# STC32G144K246 register map
Vendor: STC; File version: 2.0
Registers are 8-bit, read-write, no defined reset value unless marked. A register's access mark holds for its fields unless they carry their own. Offsets are from the block's base; [hi:lo] are bit positions; {n}, {i} and the like mark numbered series.

## GPIO7 — P7 端口、模式、上下拉和中断
Base 0x007EFD07
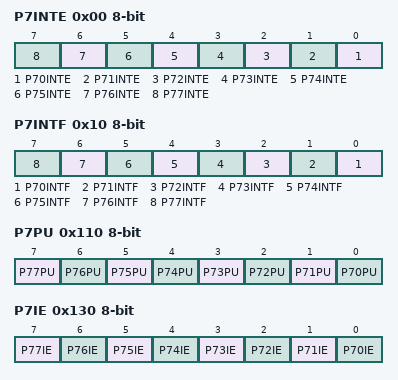
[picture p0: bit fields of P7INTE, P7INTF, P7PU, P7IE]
0x00 P7INTE — P7口中断使能寄存器
  [n-70] P{n}INTE (n=70..77) — 尚未自动匹配到此字段的独立说明；请查看下方章节说明。
0x10 P7INTF ro — P7口中断标志寄存器
  [n-70] P{n}INTF (n=70..77) — 尚未自动匹配到此字段的独立说明；请查看下方章节说明。
0x110 P7PU — P7口上拉电阻控制寄存器
  [all] fields
    0=禁止内部上拉电阻; 1=使能内部上拉电阻
  [7] P77PU — 控制 P7.7 的内部上拉电阻。
  [6] P76PU — 控制 P7.6 的内部上拉电阻。
  [5] P75PU — 控制 P7.5 的内部上拉电阻。
  [4] P74PU — 控制 P7.4 的内部上拉电阻。
  [3] P73PU — 控制 P7.3 的内部上拉电阻。
  [2] P72PU — 控制 P7.2 的内部上拉电阻。
  [1] P71PU — 控制 P7.1 的内部上拉电阻。
  [0] P70PU — 控制 P7.0 的内部上拉电阻。
0x130 P7IE — P7口输入使能控制寄存器
  [all] fields
    0=禁止数字信号输入，用于模拟功能; 1=使能数字信号输入
  [7] P77IE — 控制 P7.7 的数字信号输入。
  [6] P76IE — 控制 P7.6 的数字信号输入。
  [5] P75IE — 控制 P7.5 的数字信号输入。
  [4] P74IE — 控制 P7.4 的数字信号输入。
  [3] P73IE — 控制 P7.3 的数字信号输入。
  [2] P72IE — 控制 P7.2 的数字信号输入。
  [1] P71IE — 控制 P7.1 的数字信号输入。
  [0] P70IE — 控制 P7.0 的数字信号输入。
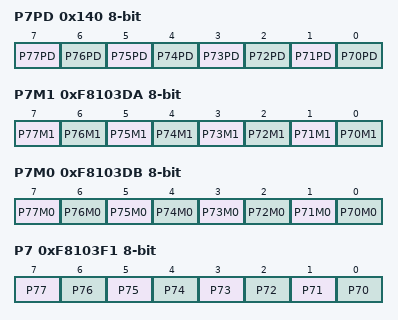
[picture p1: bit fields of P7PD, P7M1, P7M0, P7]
0x140 P7PD — P7口下拉电阻控制寄存器
  [all] fields
    0=禁止内部下拉电阻; 1=使能内部下拉电阻
  [7] P77PD — 控制 P7.7 的内部下拉电阻。
  [6] P76PD — 控制 P7.6 的内部下拉电阻。
  [5] P75PD — 控制 P7.5 的内部下拉电阻。
  [4] P74PD — 控制 P7.4 的内部下拉电阻。
  [3] P73PD — 控制 P7.3 的内部下拉电阻。
  [2] P72PD — 控制 P7.2 的内部下拉电阻。
  [1] P71PD — 控制 P7.1 的内部下拉电阻。
  [0] P70PD — 控制 P7.0 的内部下拉电阻。
0xF8103DA P7M1 — P7口配置寄存器1
  [7] P77M1 — 控制 P7.7 的端口模式高位；与 P7M0.B7 配合设置，组合含义见下表。
  [6] P76M1 — 控制 P7.6 的端口模式高位；与 P7M0.B6 配合设置，组合含义见下表。
  [5] P75M1 — 控制 P7.5 的端口模式高位；与 P7M0.B5 配合设置，组合含义见下表。
  [4] P74M1 — 控制 P7.4 的端口模式高位；与 P7M0.B4 配合设置，组合含义见下表。
  [3] P73M1 — 控制 P7.3 的端口模式高位；与 P7M0.B3 配合设置，组合含义见下表。
  [2] P72M1 — 控制 P7.2 的端口模式高位；与 P7M0.B2 配合设置，组合含义见下表。
  [1] P71M1 — 控制 P7.1 的端口模式高位；与 P7M0.B1 配合设置，组合含义见下表。
  [0] P70M1 — 控制 P7.0 的端口模式高位；与 P7M0.B0 配合设置，组合含义见下表。
0xF8103DB P7M0 — P7口配置寄存器0
  [7] P77M0 — 控制 P7.7 的端口模式低位；与 P7M1.B7 配合设置，组合含义见下表。
  [6] P76M0 — 控制 P7.6 的端口模式低位；与 P7M1.B6 配合设置，组合含义见下表。
  [5] P75M0 — 控制 P7.5 的端口模式低位；与 P7M1.B5 配合设置，组合含义见下表。
  [4] P74M0 — 控制 P7.4 的端口模式低位；与 P7M1.B4 配合设置，组合含义见下表。
  [3] P73M0 — 控制 P7.3 的端口模式低位；与 P7M1.B3 配合设置，组合含义见下表。
  [2] P72M0 — 控制 P7.2 的端口模式低位；与 P7M1.B2 配合设置，组合含义见下表。
  [1] P71M0 — 控制 P7.1 的端口模式低位；与 P7M1.B1 配合设置，组合含义见下表。
  [0] P70M0 — 控制 P7.0 的端口模式低位；与 P7M1.B0 配合设置，组合含义见下表。
0xF8103F1 P7 — P7端口
  [all] fields
    0=低电平; 1=高电平
  [7] P77 — 读取 P7.7 管脚电平；写入 P7.7 的输出缓冲区。实际输出行为由端口模式及外设复用共同决定。
  [6] P76 — 读取 P7.6 管脚电平；写入 P7.6 的输出缓冲区。实际输出行为由端口模式及外设复用共同决定。
  [5] P75 — 读取 P7.5 管脚电平；写入 P7.5 的输出缓冲区。实际输出行为由端口模式及外设复用共同决定。
  [4] P74 — 读取 P7.4 管脚电平；写入 P7.4 的输出缓冲区。实际输出行为由端口模式及外设复用共同决定。
  [3] P73 — 读取 P7.3 管脚电平；写入 P7.3 的输出缓冲区。实际输出行为由端口模式及外设复用共同决定。
  [2] P72 — 读取 P7.2 管脚电平；写入 P7.2 的输出缓冲区。实际输出行为由端口模式及外设复用共同决定。
  [1] P71 — 读取 P7.1 管脚电平；写入 P7.1 的输出缓冲区。实际输出行为由端口模式及外设复用共同决定。
  [0] P70 — 读取 P7.0 管脚电平；写入 P7.0 的输出缓冲区。实际输出行为由端口模式及外设复用共同决定。

## GPIO8 — P8 端口、模式、上下拉和中断
Base 0x007EF700
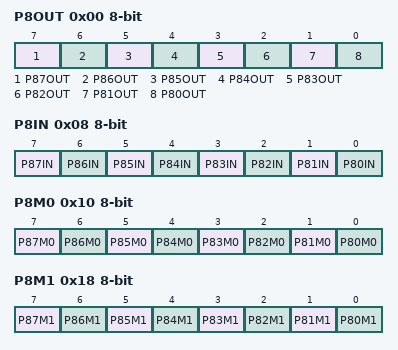
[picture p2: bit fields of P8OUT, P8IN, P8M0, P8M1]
0x00 P8OUT — P8端口输出寄存器
  [all] fields
    0=低电平; 1=高电平
  [7] P87OUT — 设置 P8.7 的输出缓冲区电平。实际输出行为由端口模式及外设复用共同决定。
  [6] P86OUT — 设置 P8.6 的输出缓冲区电平。实际输出行为由端口模式及外设复用共同决定。
  [5] P85OUT — 设置 P8.5 的输出缓冲区电平。实际输出行为由端口模式及外设复用共同决定。
  [4] P84OUT — 设置 P8.4 的输出缓冲区电平。实际输出行为由端口模式及外设复用共同决定。
  [3] P83OUT — 设置 P8.3 的输出缓冲区电平。实际输出行为由端口模式及外设复用共同决定。
  [2] P82OUT — 设置 P8.2 的输出缓冲区电平。实际输出行为由端口模式及外设复用共同决定。
  [1] P81OUT — 设置 P8.1 的输出缓冲区电平。实际输出行为由端口模式及外设复用共同决定。
  [0] P80OUT — 设置 P8.0 的输出缓冲区电平。实际输出行为由端口模式及外设复用共同决定。
0x08 P8IN ro — P8端口输入寄存器
  [all] fields
    0=低电平; 1=高电平
  [7] P87IN — 读取 P8.7 管脚上的实际电平。
  [6] P86IN — 读取 P8.6 管脚上的实际电平。
  [5] P85IN — 读取 P8.5 管脚上的实际电平。
  [4] P84IN — 读取 P8.4 管脚上的实际电平。
  [3] P83IN — 读取 P8.3 管脚上的实际电平。
  [2] P82IN — 读取 P8.2 管脚上的实际电平。
  [1] P81IN — 读取 P8.1 管脚上的实际电平。
  [0] P80IN — 读取 P8.0 管脚上的实际电平。
0x10 P8M0 — P8端口配置寄存器0
  [7] P87M0 — 控制 P8.7 的端口模式低位；与 P8M1.B7 配合设置，组合含义见下表。
  [6] P86M0 — 控制 P8.6 的端口模式低位；与 P8M1.B6 配合设置，组合含义见下表。
  [5] P85M0 — 控制 P8.5 的端口模式低位；与 P8M1.B5 配合设置，组合含义见下表。
  [4] P84M0 — 控制 P8.4 的端口模式低位；与 P8M1.B4 配合设置，组合含义见下表。
  [3] P83M0 — 控制 P8.3 的端口模式低位；与 P8M1.B3 配合设置，组合含义见下表。
  [2] P82M0 — 控制 P8.2 的端口模式低位；与 P8M1.B2 配合设置，组合含义见下表。
  [1] P81M0 — 控制 P8.1 的端口模式低位；与 P8M1.B1 配合设置，组合含义见下表。
  [0] P80M0 — 控制 P8.0 的端口模式低位；与 P8M1.B0 配合设置，组合含义见下表。
0x18 P8M1 — P8端口配置寄存器1
  [7] P87M1 — 控制 P8.7 的端口模式高位；与 P8M0.B7 配合设置，组合含义见下表。
  [6] P86M1 — 控制 P8.6 的端口模式高位；与 P8M0.B6 配合设置，组合含义见下表。
  [5] P85M1 — 控制 P8.5 的端口模式高位；与 P8M0.B5 配合设置，组合含义见下表。
  [4] P84M1 — 控制 P8.4 的端口模式高位；与 P8M0.B4 配合设置，组合含义见下表。
  [3] P83M1 — 控制 P8.3 的端口模式高位；与 P8M0.B3 配合设置，组合含义见下表。
  [2] P82M1 — 控制 P8.2 的端口模式高位；与 P8M0.B2 配合设置，组合含义见下表。
  [1] P81M1 — 控制 P8.1 的端口模式高位；与 P8M0.B1 配合设置，组合含义见下表。
  [0] P80M1 — 控制 P8.0 的端口模式高位；与 P8M0.B0 配合设置，组合含义见下表。
0x20 P8SETB wo write-1-sets — P8 输出置位命令。按位写 1 置位，写 0 不动作；通过 P8OUT 读回输出锁存值。
0x28 P8CLRB wo write-1-clears — P8 输出清零命令。按位写 1 清零，写 0 不动作；通过 P8OUT 读回输出锁存值。
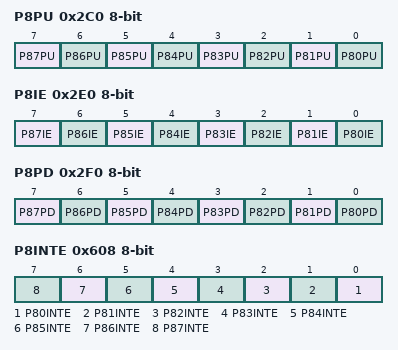
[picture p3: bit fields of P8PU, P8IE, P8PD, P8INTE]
0x2C0 P8PU — P8口上拉电阻控制寄存器
  [all] fields
    0=禁止内部上拉电阻; 1=使能内部上拉电阻
  [7] P87PU — 控制 P8.7 的内部上拉电阻。
  [6] P86PU — 控制 P8.6 的内部上拉电阻。
  [5] P85PU — 控制 P8.5 的内部上拉电阻。
  [4] P84PU — 控制 P8.4 的内部上拉电阻。
  [3] P83PU — 控制 P8.3 的内部上拉电阻。
  [2] P82PU — 控制 P8.2 的内部上拉电阻。
  [1] P81PU — 控制 P8.1 的内部上拉电阻。
  [0] P80PU — 控制 P8.0 的内部上拉电阻。
0x2E0 P8IE — P8口输入使能控制寄存器
  [all] fields
    0=禁止数字信号输入，用于模拟功能; 1=使能数字信号输入
  [7] P87IE — 控制 P8.7 的数字信号输入。
  [6] P86IE — 控制 P8.6 的数字信号输入。
  [5] P85IE — 控制 P8.5 的数字信号输入。
  [4] P84IE — 控制 P8.4 的数字信号输入。
  [3] P83IE — 控制 P8.3 的数字信号输入。
  [2] P82IE — 控制 P8.2 的数字信号输入。
  [1] P81IE — 控制 P8.1 的数字信号输入。
  [0] P80IE — 控制 P8.0 的数字信号输入。
0x2F0 P8PD — P8口下拉电阻控制寄存器
  [all] fields
    0=禁止内部下拉电阻; 1=使能内部下拉电阻
  [7] P87PD — 控制 P8.7 的内部下拉电阻。
  [6] P86PD — 控制 P8.6 的内部下拉电阻。
  [5] P85PD — 控制 P8.5 的内部下拉电阻。
  [4] P84PD — 控制 P8.4 的内部下拉电阻。
  [3] P83PD — 控制 P8.3 的内部下拉电阻。
  [2] P82PD — 控制 P8.2 的内部下拉电阻。
  [1] P81PD — 控制 P8.1 的内部下拉电阻。
  [0] P80PD — 控制 P8.0 的内部下拉电阻。
0x608 P8INTE — P8口中断使能寄存器
  [n-80] P{n}INTE (n=80..87) — 尚未自动匹配到此字段的独立说明；请查看下方章节说明。
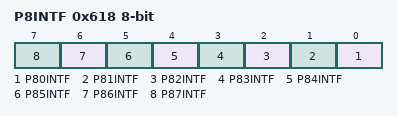
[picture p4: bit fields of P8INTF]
0x618 P8INTF ro — P8口中断标志寄存器
  [n-80] P{n}INTF (n=80..87) — 尚未自动匹配到此字段的独立说明；请查看下方章节说明。
